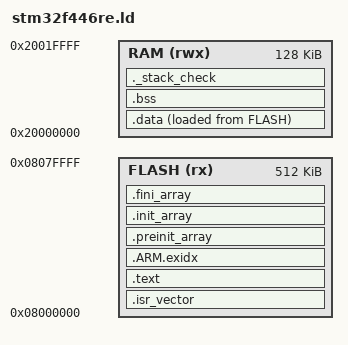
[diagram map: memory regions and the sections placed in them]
/* Linker script for STM32F446RE: 512 KB flash, 128 KB SRAM. */
ENTRY(Reset_Handler)

MEMORY
{
  FLASH (rx)  : ORIGIN = 0x08000000, LENGTH = 512K
  RAM   (rwx) : ORIGIN = 0x20000000, LENGTH = 128K
}

_estack = ORIGIN(RAM) + LENGTH(RAM);
_min_stack = 0x1000;

SECTIONS
{
  .isr_vector : { KEEP(*(.isr_vector)) } > FLASH

  .text :
  {
    . = ALIGN(4);
    *(.text*)
    *(.rodata*)
    KEEP(*(.init))
    KEEP(*(.fini))
    . = ALIGN(4);
  } > FLASH

  .ARM.exidx : { *(.ARM.exidx* .gnu.linkonce.armexidx.*) } > FLASH

  .preinit_array : { PROVIDE_HIDDEN(__preinit_array_start = .); KEEP(*(.preinit_array*)) PROVIDE_HIDDEN(__preinit_array_end = .); } > FLASH
  .init_array    : { PROVIDE_HIDDEN(__init_array_start = .);    KEEP(*(SORT(.init_array.*))) KEEP(*(.init_array*)) PROVIDE_HIDDEN(__init_array_end = .); } > FLASH
  .fini_array    : { PROVIDE_HIDDEN(__fini_array_start = .);    KEEP(*(SORT(.fini_array.*))) KEEP(*(.fini_array*)) PROVIDE_HIDDEN(__fini_array_end = .); } > FLASH

  _sidata = LOADADDR(.data);
  .data :
  {
    . = ALIGN(4);
    _sdata = .;
    *(.data*)
    . = ALIGN(4);
    _edata = .;
  } > RAM AT > FLASH

  .bss (NOLOAD) :
  {
    . = ALIGN(4);
    _sbss = .;
    *(.bss*)
    *(COMMON)
    . = ALIGN(4);
    _ebss = .;
    end = .;
    _end = .;
  } > RAM

  ._stack_check (NOLOAD) :
  {
    . = ALIGN(8);
    . = . + _min_stack;
  } > RAM
}
